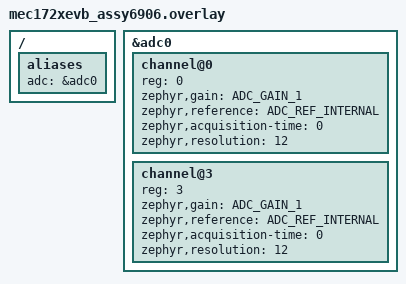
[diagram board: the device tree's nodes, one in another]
/*
 * Copyright (c) 2024 Centro de Inovacao EDGE
 *
 * SPDX-License-Identifier: Apache-2.0
 */

/ {
	aliases {
		adc = &adc0;
	};
};

&adc0 {
	#address-cells = <1>;
	#size-cells = <0>;

	channel@0 {
		reg = <0>;
		zephyr,gain = "ADC_GAIN_1";
		zephyr,reference = "ADC_REF_INTERNAL";
		zephyr,acquisition-time = <0>;
		zephyr,resolution = <12>;
	};

	channel@3 {
		reg = <3>;
		zephyr,gain = "ADC_GAIN_1";
		zephyr,reference = "ADC_REF_INTERNAL";
		zephyr,acquisition-time = <0>;
		zephyr,resolution = <12>;
	};
};
